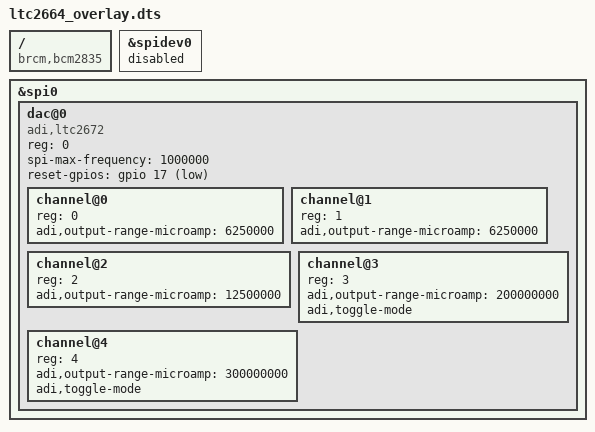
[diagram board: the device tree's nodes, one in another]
/dts-v1/;
/plugin/;

/ {
	compatible = "brcm,bcm2835", "brcm,bcm2708", "brcm,bcm2709";
};

&spidev0 {
	status = "disabled";
};

&spi0 {
	#address-cells = <1>;
	#size-cells = <0>;
	status = "okay";

	dac@0 {
		compatible = "adi,ltc2672";
                // compatible = "adi,ltc2664";
		reg = <0>;
		spi-max-frequency = <1000000>;

                reset-gpios = <&gpio 17 1>;

		#address-cells = <1>;
		#size-cells = <0>;

                channel@0 {
                        reg = <0>;
                        adi,output-range-microamp = <6250000>;
                        // adi,output-range-microvolt = <0 10000000>;
                };

                channel@1 {
                        reg = <1>;
                        adi,output-range-microamp = <6250000>;
                        // adi,output-range-microvolt = <0 10000000>;
                };

                channel@2 {
                        reg = <2>;
                        adi,output-range-microamp = <12500000>;
                        // adi,output-range-microvolt = <0 10000000>;
                };

                channel@3 {
                        reg = <3>;
                        adi,output-range-microamp = <200000000>;
                        // adi,output-range-microvolt = <0 10000000>;
                        adi,toggle-mode;
                };

                channel@4 {
                        reg = <4>;
                        adi,output-range-microamp = <300000000>;
                        adi,toggle-mode;
                };
	};
};
